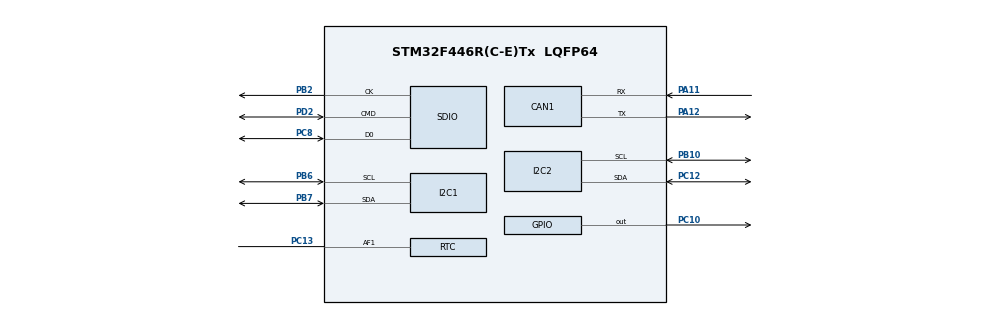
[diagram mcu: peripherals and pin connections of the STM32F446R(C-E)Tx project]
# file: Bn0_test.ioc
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CAN1.CalculateTimeQuantum=1000.0
FREERTOS.Tasks01=defaultTask,0,128,StartDefaultTask,Default,NULL
Mcu.Family=STM32F4
Mcu.Name=STM32F446R(C-E)Tx
Mcu.Package=LQFP64
NVIC.I2C1_EV_IRQn=true\:5\:0\:false\:false\:true\:true\:true
NVIC.PriorityGroup=NVIC_PRIORITYGROUP_4
NVIC.TIM6_DAC_IRQn=true\:0\:0\:false\:false\:true\:false\:false
NVIC.TimeBase=TIM6_DAC_IRQn
NVIC.TimeBaseIP=TIM6
PA11.Mode=Master
PA11.Signal=CAN1_RX
PA12.Mode=Master
PA12.Signal=CAN1_TX
PB10.Mode=I2C
PB10.Signal=I2C2_SCL
PB2.Mode=SD_1_bit
PB2.Signal=SDIO_CK
PB6.Mode=I2C
PB6.Signal=I2C1_SCL
PB7.Mode=I2C
PB7.Signal=I2C1_SDA
PC10.Signal=GPIO_Output
PC12.Mode=I2C
PC12.Signal=I2C2_SDA
PC13.Mode=Calibration_512Hz
PC13.Signal=RTC_AF1
PC8.Mode=SD_1_bit
PC8.Signal=SDIO_D0
PD2.Mode=SD_1_bit
PD2.Signal=SDIO_CMD
ProjectManager.HeapSize=0x2000
ProjectManager.StackSize=0x4000
ProjectManager.TargetToolchain=TrueSTUDIO
RCC.CortexFreq_Value=16000000
RCC.PLLM=8
RCC.PLLN=72
RCC.PLLQ=3
RCC.USBFreq_Value=48000000
RCC.VCOOutputFreq_Value=144000000
RTC.Date=17
RTC.DayLightSaving=RTC_DAYLIGHTSAVING_NONE
RTC.Month=RTC_MONTH_AUGUST
RTC.WeekDay=RTC_WEEKDAY_SATURDAY
VP_FATFS_VS_SDIO.Mode=SDIO
VP_FREERTOS_VS_ENABLE.Mode=Enabled
VP_RTC_VS_RTC_Activate.Mode=RTC_Enabled
VP_RTC_VS_RTC_Calendar.Mode=RTC_Calendar
VP_SYS_VS_tim6.Mode=TIM6
board=custom

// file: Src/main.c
/* USER CODE BEGIN Header */
/**
  ******************************************************************************
  * @file           : main.c
  * @brief          : Main program body
  ******************************************************************************
  * This notice applies to any and all portions of this file
  * that are not between comment pairs USER CODE BEGIN and
  * USER CODE END. Other portions of this file, whether
  * inserted by the user or by software development tools
  * are owned by their respective copyright owners.
  *
  * Copyright (c) 2019 STMicroelectronics International N.V.
  * All rights reserved.
  *
  * Redistribution and use in source and binary forms, with or without
  * modification, are permitted, provided that the following conditions are met:
  *
  * 1. Redistribution of source code must retain the above copyright notice,
  *    this list of conditions and the following disclaimer.
  * 2. Redistributions in binary form must reproduce the above copyright notice,
  *    this list of conditions and the following disclaimer in the documentation
  *    and/or other materials provided with the distribution.
  * 3. Neither the name of STMicroelectronics nor the names of other
  *    contributors to this software may be used to endorse or promote products
  *    derived from this software without specific written permission.
  * 4. This software, including modifications and/or derivative works of this
  *    software, must execute solely and exclusively on microcontroller or
  *    microprocessor devices manufactured by or for STMicroelectronics.
  * 5. Redistribution and use of this software other than as permitted under
  *    this license is void and will automatically terminate your rights under
  *    this license.
  *
  * THIS SOFTWARE IS PROVIDED BY STMICROELECTRONICS AND CONTRIBUTORS "AS IS"
  * AND ANY EXPRESS, IMPLIED OR STATUTORY WARRANTIES, INCLUDING, BUT NOT
  * LIMITED TO, THE IMPLIED WARRANTIES OF MERCHANTABILITY, FITNESS FOR A
  * PARTICULAR PURPOSE AND NON-INFRINGEMENT OF THIRD PARTY INTELLECTUAL PROPERTY
  * RIGHTS ARE DISCLAIMED TO THE FULLEST EXTENT PERMITTED BY LAW. IN NO EVENT
  * SHALL STMICROELECTRONICS OR CONTRIBUTORS BE LIABLE FOR ANY DIRECT, INDIRECT,
  * INCIDENTAL, SPECIAL, EXEMPLARY, OR CONSEQUENTIAL DAMAGES (INCLUDING, BUT NOT
  * LIMITED TO, PROCUREMENT OF SUBSTITUTE GOODS OR SERVICES; LOSS OF USE, DATA,
  * OR PROFITS; OR BUSINESS INTERRUPTION) HOWEVER CAUSED AND ON ANY THEORY OF
  * LIABILITY, WHETHER IN CONTRACT, STRICT LIABILITY, OR TORT (INCLUDING
  * NEGLIGENCE OR OTHERWISE) ARISING IN ANY WAY OUT OF THE USE OF THIS SOFTWARE,
  * EVEN IF ADVISED OF THE POSSIBILITY OF SUCH DAMAGE.
  *
  ******************************************************************************
  */
/* USER CODE END Header */

#include "main.h"
#include "cmsis_os.h"
#include "fatfs.h"

/* USER CODE BEGIN Includes */
#include "SDCard.h"
#include "Satellite.h"
#include "bn0.h"
/* USER CODE END Includes */

CAN_HandleTypeDef hcan1;

RTC_HandleTypeDef hrtc;

SD_HandleTypeDef hsd;

osThreadId defaultTaskHandle;

void SystemClock_Config(void);
static void MX_GPIO_Init(void);
static void MX_CAN1_Init(void);
static void MX_I2C1_Init(void);
static void MX_SDIO_SD_Init(void);
static void MX_RTC_Init(void);
static void MX_I2C2_Init(void);
void StartDefaultTask(void const * argument);

/* USER CODE BEGIN PFP */
void vTaskBNOData(void *pvParameters){
	for(;;){
//		if(xSemaphoreTake(gateKeeper,1000)){
			logGravData();
//			xSemaphoreGive(gateKeeper);
//		}
		vTaskDelay(100/portTICK_PERIOD_MS);
	}
}
/* USER CODE END PFP */

int main(void)
{

  /* MCU Configuration--------------------------------------------------------*/

  /* Reset of all peripherals, Initializes the Flash interface and the Systick. */
  HAL_Init();

  /* Configure the system clock */
  SystemClock_Config();

  /* Initialize all configured peripherals */
  MX_GPIO_Init();
  MX_CAN1_Init();
  MX_I2C1_Init();
  MX_SDIO_SD_Init();
  MX_RTC_Init();
  MX_I2C2_Init();
  /* USER CODE BEGIN 2 */
  initFileSystem();
  bnO_init(&hi2c1,OPERATION_MODE_NDOF);
  BaseType_t BNOTask;
  BNOTask = xTaskCreate(vTaskBNOData,(const char* const)"BNO",configMINIMAL_STACK_SIZE,NULL,2,NULL);
  /* USER CODE END 2 */

  /* Create the thread(s) */
  /* definition and creation of defaultTask */
  osThreadDef(defaultTask, StartDefaultTask, osPriorityNormal, 0, 128);
  defaultTaskHandle = osThreadCreate(osThread(defaultTask), NULL);

  /* Start scheduler */
  osKernelStart();

  /* We should never get here as control is now taken by the scheduler */

  /* Infinite loop */
  while (1)
  {

  }
}

void SystemClock_Config(void)
{
  RCC_OscInitTypeDef RCC_OscInitStruct = {0};
  RCC_ClkInitTypeDef RCC_ClkInitStruct = {0};
  RCC_PeriphCLKInitTypeDef PeriphClkInitStruct = {0};

  /**Configure the main internal regulator output voltage
  */
  __HAL_RCC_PWR_CLK_ENABLE();
  __HAL_PWR_VOLTAGESCALING_CONFIG(PWR_REGULATOR_VOLTAGE_SCALE3);
  /**Initializes the CPU, AHB and APB busses clocks
  */
  RCC_OscInitStruct.OscillatorType = RCC_OSCILLATORTYPE_HSI|RCC_OSCILLATORTYPE_LSI;
  RCC_OscInitStruct.LSEState = RCC_LSE_OFF;
  RCC_OscInitStruct.HSIState = RCC_HSI_ON;
  RCC_OscInitStruct.HSICalibrationValue = RCC_HSICALIBRATION_DEFAULT;
  RCC_OscInitStruct.LSIState = RCC_LSI_ON;
  RCC_OscInitStruct.PLL.PLLState = RCC_PLL_ON;
  RCC_OscInitStruct.PLL.PLLSource = RCC_PLLSOURCE_HSI;
  RCC_OscInitStruct.PLL.PLLM = 8;
  RCC_OscInitStruct.PLL.PLLN = 72;
  RCC_OscInitStruct.PLL.PLLP = RCC_PLLP_DIV2;
  RCC_OscInitStruct.PLL.PLLQ = 3;
  RCC_OscInitStruct.PLL.PLLR = 2;
  if (HAL_RCC_OscConfig(&RCC_OscInitStruct) != HAL_OK)
  {
    Error_Handler();
  }
  /**Initializes the CPU, AHB and APB busses clocks
  */
  RCC_ClkInitStruct.ClockType = RCC_CLOCKTYPE_HCLK|RCC_CLOCKTYPE_SYSCLK
                              |RCC_CLOCKTYPE_PCLK1|RCC_CLOCKTYPE_PCLK2;
  RCC_ClkInitStruct.SYSCLKSource = RCC_SYSCLKSOURCE_HSI;
  RCC_ClkInitStruct.AHBCLKDivider = RCC_SYSCLK_DIV1;
  RCC_ClkInitStruct.APB1CLKDivider = RCC_HCLK_DIV1;
  RCC_ClkInitStruct.APB2CLKDivider = RCC_HCLK_DIV1;

  if (HAL_RCC_ClockConfig(&RCC_ClkInitStruct, FLASH_LATENCY_0) != HAL_OK)
  {
    Error_Handler();
  }
  PeriphClkInitStruct.PeriphClockSelection = RCC_PERIPHCLK_RTC|RCC_PERIPHCLK_SDIO
                              |RCC_PERIPHCLK_CLK48;
  PeriphClkInitStruct.RTCClockSelection = RCC_RTCCLKSOURCE_LSI;
  PeriphClkInitStruct.Clk48ClockSelection = RCC_CLK48CLKSOURCE_PLLQ;
  PeriphClkInitStruct.SdioClockSelection = RCC_SDIOCLKSOURCE_CLK48;
  if (HAL_RCCEx_PeriphCLKConfig(&PeriphClkInitStruct) != HAL_OK)
  {
    Error_Handler();
  }
}

static void MX_CAN1_Init(void)
{

  hcan1.Instance = CAN1;
  hcan1.Init.Prescaler = 16;
  hcan1.Init.Mode = CAN_MODE_NORMAL;
  hcan1.Init.SyncJumpWidth = CAN_SJW_1TQ;
  hcan1.Init.TimeSeg1 = CAN_BS1_1TQ;
  hcan1.Init.TimeSeg2 = CAN_BS2_1TQ;
  hcan1.Init.TimeTriggeredMode = DISABLE;
  hcan1.Init.AutoBusOff = DISABLE;
  hcan1.Init.AutoWakeUp = DISABLE;
  hcan1.Init.AutoRetransmission = DISABLE;
  hcan1.Init.ReceiveFifoLocked = DISABLE;
  hcan1.Init.TransmitFifoPriority = DISABLE;
  if (HAL_CAN_Init(&hcan1) != HAL_OK)
  {
    Error_Handler();
  }

}

static void MX_I2C1_Init(void)
{

  hi2c1.Instance = I2C1;
  hi2c1.Init.ClockSpeed = 100000;
  hi2c1.Init.DutyCycle = I2C_DUTYCYCLE_2;
  hi2c1.Init.OwnAddress1 = 0;
  hi2c1.Init.AddressingMode = I2C_ADDRESSINGMODE_7BIT;
  hi2c1.Init.DualAddressMode = I2C_DUALADDRESS_DISABLE;
  hi2c1.Init.OwnAddress2 = 0;
  hi2c1.Init.GeneralCallMode = I2C_GENERALCALL_DISABLE;
  hi2c1.Init.NoStretchMode = I2C_NOSTRETCH_DISABLE;
  if (HAL_I2C_Init(&hi2c1) != HAL_OK)
  {
    Error_Handler();
  }

}

static void MX_I2C2_Init(void)
{

  hi2c2.Instance = I2C2;
  hi2c2.Init.ClockSpeed = 100000;
  hi2c2.Init.DutyCycle = I2C_DUTYCYCLE_2;
  hi2c2.Init.OwnAddress1 = 0;
  hi2c2.Init.AddressingMode = I2C_ADDRESSINGMODE_7BIT;
  hi2c2.Init.DualAddressMode = I2C_DUALADDRESS_DISABLE;
  hi2c2.Init.OwnAddress2 = 0;
  hi2c2.Init.GeneralCallMode = I2C_GENERALCALL_DISABLE;
  hi2c2.Init.NoStretchMode = I2C_NOSTRETCH_DISABLE;
  if (HAL_I2C_Init(&hi2c2) != HAL_OK)
  {
    Error_Handler();
  }

}

static void MX_RTC_Init(void)
{

  RTC_TimeTypeDef sTime = {0};
  RTC_DateTypeDef sDate = {0};

  /**Initialize RTC Only
  */
  hrtc.Instance = RTC;
  hrtc.Init.HourFormat = RTC_HOURFORMAT_24;
  hrtc.Init.AsynchPrediv = 127;
  hrtc.Init.SynchPrediv = 255;
  hrtc.Init.OutPut = RTC_OUTPUT_DISABLE;
  hrtc.Init.OutPutPolarity = RTC_OUTPUT_POLARITY_HIGH;
  hrtc.Init.OutPutType = RTC_OUTPUT_TYPE_OPENDRAIN;
  if (HAL_RTC_Init(&hrtc) != HAL_OK)
  {
    Error_Handler();
  }

  /**Initialize RTC and set the Time and Date
  */
  sTime.Hours = 0x0;
  sTime.Minutes = 0x0;
  sTime.Seconds = 0x0;
  sTime.DayLightSaving = RTC_DAYLIGHTSAVING_NONE;
  sTime.StoreOperation = RTC_STOREOPERATION_RESET;
  if (HAL_RTC_SetTime(&hrtc, &sTime, RTC_FORMAT_BCD) != HAL_OK)
  {
    Error_Handler();
  }
  sDate.WeekDay = RTC_WEEKDAY_SATURDAY;
  sDate.Month = RTC_MONTH_AUGUST;
  sDate.Date = 0x17;
  sDate.Year = 0x0;

  if (HAL_RTC_SetDate(&hrtc, &sDate, RTC_FORMAT_BCD) != HAL_OK)
  {
    Error_Handler();
  }
  /**Enable Calibrartion
  */
  if (HAL_RTCEx_SetCalibrationOutPut(&hrtc, RTC_CALIBOUTPUT_512HZ) != HAL_OK)
  {
    Error_Handler();
  }

}

static void MX_SDIO_SD_Init(void)
{

  hsd.Instance = SDIO;
  hsd.Init.ClockEdge = SDIO_CLOCK_EDGE_RISING;
  hsd.Init.ClockBypass = SDIO_CLOCK_BYPASS_DISABLE;
  hsd.Init.ClockPowerSave = SDIO_CLOCK_POWER_SAVE_DISABLE;
  hsd.Init.BusWide = SDIO_BUS_WIDE_1B;
  hsd.Init.HardwareFlowControl = SDIO_HARDWARE_FLOW_CONTROL_DISABLE;
  hsd.Init.ClockDiv = 0;

}

static void MX_GPIO_Init(void)
{
  GPIO_InitTypeDef GPIO_InitStruct = {0};

  /* GPIO Ports Clock Enable */
  __HAL_RCC_GPIOC_CLK_ENABLE();
  __HAL_RCC_GPIOB_CLK_ENABLE();
  __HAL_RCC_GPIOA_CLK_ENABLE();
  __HAL_RCC_GPIOD_CLK_ENABLE();

  /*Configure GPIO pin Output Level */
  HAL_GPIO_WritePin(GPIOC, GPIO_PIN_10, GPIO_PIN_RESET);

  /*Configure GPIO pin : PC10 */
  GPIO_InitStruct.Pin = GPIO_PIN_10;
  GPIO_InitStruct.Mode = GPIO_MODE_OUTPUT_PP;
  GPIO_InitStruct.Pull = GPIO_NOPULL;
  GPIO_InitStruct.Speed = GPIO_SPEED_FREQ_LOW;
  HAL_GPIO_Init(GPIOC, &GPIO_InitStruct);

}

void StartDefaultTask(void const * argument)
{
  /* init code for FATFS */
  MX_FATFS_Init();

  for(;;)
  {
    osDelay(1);
  }
}

void HAL_TIM_PeriodElapsedCallback(TIM_HandleTypeDef *htim)
{
  if (htim->Instance == TIM6) {
    HAL_IncTick();
  }
}

void Error_Handler(void)
{
}

/************************ (C) COPYRIGHT STMicroelectronics *****END OF FILE****/
